AUTOSAR XML (schema 4-3-0)
package /CollisionDetectionBSW/Services/EcuM
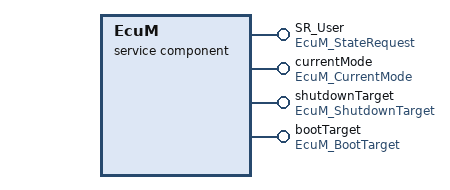
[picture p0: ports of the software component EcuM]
  service sw component type EcuM
    4 x provide port:
      SR_User: provided-interface=EcuM_StateRequest
      currentMode: provided-interface=EcuM_CurrentMode
      shutdownTarget: provided-interface=EcuM_ShutdownTarget
      bootTarget: provided-interface=EcuM_BootTarget
    behavior EcuMFixedBehavior: data-type-mapping=EcuMFixedTypeMappings, handle-termination-and-restart=NO-SUPPORT, port-api-option{port-defined-argument-value{value=EcuM_UserType:0, value-type=EcuM_UserType}, port=SR_User}
      9 x operation invoked event:
        RequestRUN_SR_User_RequestRUN: start-on-event=RequestRUN, operation=SR_User.RequestRUN
        ReleaseRUN_SR_User_ReleaseRUN: start-on-event=ReleaseRUN, operation=SR_User.ReleaseRUN
        RequestPOSTRUN_SR_User_RequestPOSTRUN: start-on-event=RequestPOSTRUN, operation=SR_User.RequestPOSTRUN
        ReleasePOSTRUN_SR_User_ReleasePOSTRUN: start-on-event=ReleasePOSTRUN, operation=SR_User.ReleasePOSTRUN
        SelectShutdownTarget_shutdownTarget_SelectShutdownTarget: start-on-event=SelectShutdownTarget, operation=shutdownTarget.SelectShutdownTarget
        GetShutdownTarget_shutdownTarget_GetShutdownTarget: start-on-event=GetShutdownTarget, operation=shutdownTarget.GetShutdownTarget
        GetLastShutdownTarget_shutdownTarget_GetLastShutdownTarget: start-on-event=GetLastShutdownTarget, operation=shutdownTarget.GetLastShutdownTarget
        SelectBootTarget_bootTarget_SelectBootTarget: start-on-event=SelectBootTarget, operation=bootTarget.SelectBootTarget
        GetBootTarget_bootTarget_GetBootTarget: start-on-event=GetBootTarget, operation=bootTarget.GetBootTarget
      10 x runnable:
        EcuM_MainFunction
          mode switch point modeSwitchPoint_EcuM_MainFunction_currentMode_currentMode: mode-group=currentMode.currentMode
        RequestRUN: can-be-invoked-concurrently=true, symbol=EcuM_RequestRUN
        ReleaseRUN: can-be-invoked-concurrently=true, symbol=EcuM_ReleaseRUN
        RequestPOSTRUN: can-be-invoked-concurrently=true, symbol=EcuM_RequestPOST_RUN
        ReleasePOSTRUN: can-be-invoked-concurrently=true, symbol=EcuM_ReleasePOST_RUN
        SelectShutdownTarget: can-be-invoked-concurrently=true, symbol=EcuM_SelectShutdownTarget
        GetShutdownTarget: can-be-invoked-concurrently=true, symbol=EcuM_GetShutdownTarget
        GetLastShutdownTarget: can-be-invoked-concurrently=true, symbol=EcuM_GetLastShutdownTarget
        SelectBootTarget: can-be-invoked-concurrently=true, symbol=EcuM_SelectBootTarget
        GetBootTarget: can-be-invoked-concurrently=true, symbol=EcuM_GetBootTarget
  swc implementation EcuMFixedImpl: programming-language=C, vendor-id=60, behavior=EcuMFixedBehavior
    code-descriptors:
      code src: artifact-descriptors=autosar-engineering-object={short-label=artifactDescriptor, category=artifactDescriptorCategory}
    resource consumption resourceConsumption
